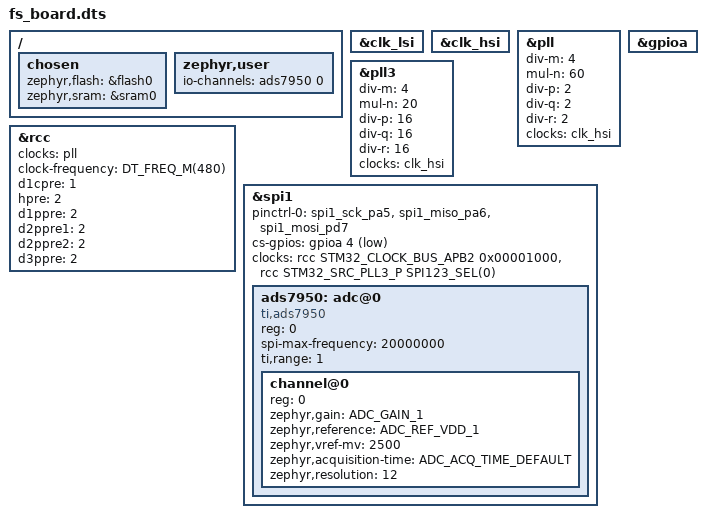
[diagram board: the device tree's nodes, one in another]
/dts-v1/;
#include <st/h7/stm32h750Xb.dtsi>
#include <st/h7/stm32h750vbtx-pinctrl.dtsi>
#include <zephyr/dt-bindings/input/input-event-codes.h>
#include <zephyr/dt-bindings/clock/stm32h7_clock.h>

/ {
    chosen {
        zephyr,flash = &flash0;
        zephyr,sram = &sram0;
    };

    zephyr,user {
        io-channels = <&ads7950 0>;
        io-channel-names = "ain0";
    };
};

&clk_lsi {
    status = "okay";
};

&clk_hsi {
    status = "okay";
};

&pll {
    div-m = <4>;
    mul-n = <60>;
    div-p = <2>;
    div-q = <2>;
    div-r = <2>;
    clocks = <&clk_hsi>;
    status = "okay";
};

&rcc {
    clocks = <&pll>;
    clock-frequency = <DT_FREQ_M(480)>;
    d1cpre = <1>;
    hpre = <2>;
    d1ppre = <2>;
    d2ppre1 = <2>;
    d2ppre2 = <2>;
    d3ppre = <2>;
    status = "okay";
};

&gpioa {
    status = "okay";
};

&pll3 {
    div-m = <4>;    /* 64 / 4 = 16MHz (VCO input) */
    mul-n = <20>;   /* 16 * 20 = 320MHz (VCO output, within 150-800MHz range) */
    div-p = <16>;   /* 320 / 16 = 20MHz (SPI Clock) */
    div-q = <16>;   /* Keep consistent or adjust as needed */
    div-r = <16>;
    clocks = <&clk_hsi>;
    status = "okay";
};

&spi1 {
    status = "okay";
    pinctrl-names = "default";
    /* Note: PD7 vs PA7 for MOSI based on hardware design */
    pinctrl-0 = <&spi1_sck_pa5 &spi1_miso_pa6 &spi1_mosi_pd7>;
    cs-gpios = <&gpioa 4 GPIO_ACTIVE_LOW>;

    #address-cells = <1>; // Sub-node 'reg' uses 1 cell for address
    #size-cells = <0>;    // Sub-node 'reg' does not require size

    /* Explicitly define clocks to use PLL3 as the Kernel Clock source */
    clocks = <&rcc STM32_CLOCK_BUS_APB2 0x00001000>,
             <&rcc STM32_SRC_PLL3_P SPI123_SEL(0)>;

    ads7950: adc@0 {
        compatible = "ti,ads7950";
        reg = <0>; // Address format defined by parent node (spi1)
        spi-max-frequency = <20000000>;
        #io-channel-cells = <1>; // Number of cells to specify the channel
        ti,range = <1>;          // 1 = 0..Vref, 2 = 0..2*Vref
        status = "okay";

        /* --- ADC Driver Configuration (Temporarily Unused) --- */
        #address-cells = <1>;
        #size-cells = <0>;
        channel@0 {
            reg = <0>;
            zephyr,gain = "ADC_GAIN_1";
            zephyr,reference = "ADC_REF_VDD_1"; /*ADC_REF_EXTERNAL0*/
            // Use 3300 for 3.3V REFP, or 2500 for a 2.5V reference IC
            zephyr,vref-mv = <2500>;
            zephyr,acquisition-time = <ADC_ACQ_TIME_DEFAULT>;
            zephyr,resolution = <12>;
        };

    };
};
